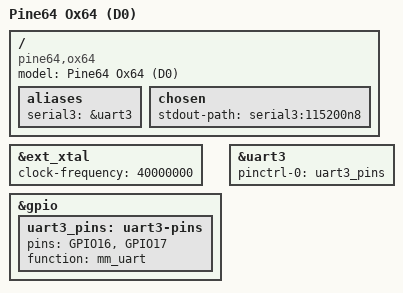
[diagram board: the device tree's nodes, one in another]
// SPDX-License-Identifier: GPL-2.0+

/dts-v1/;

#include "bl808-d0.dtsi"

/ {
	compatible = "pine64,ox64", "bflb,bl808";
	model = "Pine64 Ox64 (D0)";

	aliases {
		serial3 = &uart3;
	};

	chosen {
		stdout-path = "serial3:115200n8";
	};
};

&ext_xtal {
	clock-frequency = <40000000>;
};

&gpio {
	uart3_pins: uart3-pins {
		pins = "GPIO16", "GPIO17";
		function = "mm_uart";
	};
};

&uart3 {
	pinctrl-0 = <&uart3_pins>;
	pinctrl-names = "default";
	status = "okay";
};
